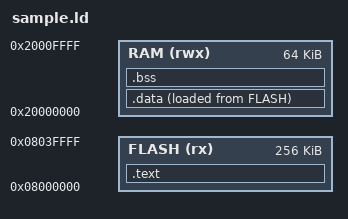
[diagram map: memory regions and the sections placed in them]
MEMORY
{
  FLASH (rx)  : ORIGIN = 0x08000000, LENGTH = 256K
  RAM   (rwx) : ORIGIN = 0x20000000, LENGTH = 64K
}

SECTIONS
{
  .text : ALIGN(4)
  {
    KEEP(*(.isr_vector))
    *(.text*)
    *(.rodata*)
  } > FLASH

  .data :
  {
    *(.data*)
  } > RAM AT > FLASH

  .bss :
  {
    *(.bss*)
  } > RAM
}
